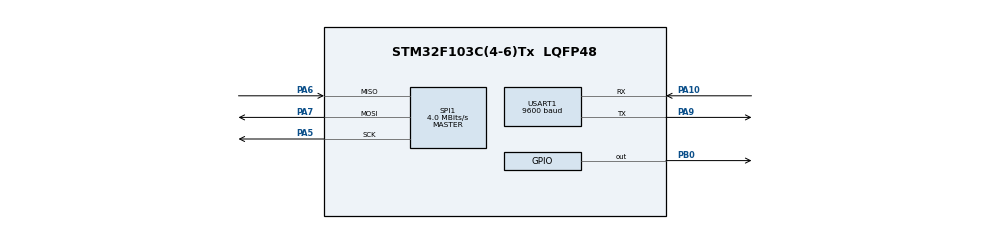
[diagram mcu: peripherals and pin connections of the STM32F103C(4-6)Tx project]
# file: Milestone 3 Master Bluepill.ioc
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Mcu.Family=STM32F1
Mcu.Name=STM32F103C(4-6)Tx
Mcu.Package=LQFP48
NVIC.PriorityGroup=NVIC_PRIORITYGROUP_4
PA10.Mode=Asynchronous
PA10.Signal=USART1_RX
PA5.Mode=Full_Duplex_Master
PA5.Signal=SPI1_SCK
PA6.Mode=Full_Duplex_Master
PA6.Signal=SPI1_MISO
PA7.Mode=Full_Duplex_Master
PA7.Signal=SPI1_MOSI
PA9.Mode=Asynchronous
PA9.Signal=USART1_TX
PB0.Signal=GPIO_Output
ProjectManager.HeapSize=0x200
ProjectManager.StackSize=0x400
ProjectManager.TargetToolchain=STM32CubeIDE
RCC.APB1Freq_Value=8000000
RCC.APB2Freq_Value=8000000
SPI1.CalculateBaudRate=4.0 MBits/s
SPI1.Direction=SPI_DIRECTION_2LINES
SPI1.Mode=SPI_MODE_MASTER
SPI1.VirtualType=VM_MASTER
USART1.BaudRate=9600
USART1.VirtualMode=VM_ASYNC
VP_SYS_VS_ND.Mode=No_Debug
board=custom

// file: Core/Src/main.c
/* USER CODE BEGIN Header */
/**
  ******************************************************************************
  * @file           : main.c
  * @brief          : Main program body
  ******************************************************************************
  * @attention
  *
  * Copyright (c) 2026 STMicroelectronics.
  * All rights reserved.
  *
  * This software is licensed under terms that can be found in the LICENSE file
  * in the root directory of this software component.
  * If no LICENSE file comes with this software, it is provided AS-IS.
  *
  ******************************************************************************
  */
/* USER CODE END Header */
#include "main.h"
#include "string.h"
#include <stdio.h>
#include <stdlib.h>

SPI_HandleTypeDef hspi1;

UART_HandleTypeDef huart1;

void SystemClock_Config(void);
static void MX_GPIO_Init(void);
static void MX_SPI1_Init(void);
static void MX_USART1_UART_Init(void);

/* USER CODE BEGIN 0 */

#pragma pack(push, 1)
struct motor_data {
    uint8_t voltage_x10; // 1 byte
    uint16_t speed;      // 2 bytes
};                       // total = 3 bytes = 24 bits
#pragma pack(pop)

/* USER CODE END 0 */
void UART_ReadLine(UART_HandleTypeDef *huart, char *buf, uint16_t max_len)
{
    uint16_t idx = 0;
    uint8_t ch = 0;

    while (idx < max_len - 1)
    {
        // Receive 1 byte (blocking)
        if (HAL_UART_Receive(huart, &ch, 1, HAL_MAX_DELAY) == HAL_OK)
        {
            // Echo character back to the terminal so the user sees what they type
            HAL_UART_Transmit(huart, &ch, 1, 10);

            // Handle newline or carriage return
            if (ch == '\r' || ch == '\n')
            {
                if (idx > 0) break; // Avoid empty inputs if terminal sends \r\n together
                continue;
            }
            // Handle backspace
            else if (ch == '\b' || ch == 127)
            {
                if (idx > 0)
                {
                    idx--;
                    // Erase character on terminal screen
                    char bs_seq[] = " \b";
                    HAL_UART_Transmit(huart, (uint8_t *)bs_seq, 2, 10);
                }
            }
            else
            {
                buf[idx++] = (char)ch;
            }
        }
    }
    buf[idx] = '\0'; // Null-terminate string

    // Print newline on terminal
    char newline[] = "\r\n";
    HAL_UART_Transmit(huart, (uint8_t *)newline, 2, 10);
}

int main(void)
{

  /* MCU Configuration--------------------------------------------------------*/

  /* Reset of all peripherals, Initializes the Flash interface and the Systick. */
  HAL_Init();

  /* Configure the system clock */
  SystemClock_Config();

  /* Initialize all configured peripherals */
  MX_GPIO_Init();
  MX_SPI1_Init();
  MX_USART1_UART_Init();
  /* USER CODE BEGIN 2 */
  struct motor_data rx_data;

  uint16_t case_id = 0x1001;

  const char first_msg[] = "Please enter case id: 0x";
  char send_msg_buffer[50];
  char receive_msg_buffer[32];
  /* USER CODE END 2 */

  /* Infinite loop */
  /* USER CODE BEGIN WHILE */
  while (1)
    {
	  HAL_UART_Transmit(&huart1, (uint8_t*)first_msg, strlen(first_msg), 100);

	  UART_ReadLine(&huart1, receive_msg_buffer, sizeof(receive_msg_buffer));

	  // Convert ASCII hex string to uint16_t
	  case_id = (uint16_t) strtol(receive_msg_buffer, NULL, 16);

      HAL_GPIO_WritePin(GPIOB, GPIO_PIN_0, GPIO_PIN_RESET);
      HAL_SPI_Transmit(&hspi1, (uint8_t *)&case_id, sizeof(case_id), 100);
      HAL_SPI_Receive(&hspi1, (uint8_t *)&rx_data, sizeof(rx_data), 100);
      HAL_GPIO_WritePin(GPIOB, GPIO_PIN_0, GPIO_PIN_SET);

      //PRINT DATA
      snprintf(send_msg_buffer, sizeof(send_msg_buffer),
                   "Voltage: %d.%d V | Speed: %u RPM\r\n",
                   rx_data.voltage_x10 / 10, rx_data.voltage_x10 % 10, rx_data.speed);

      HAL_UART_Transmit(&huart1, (uint8_t*)send_msg_buffer, strlen(send_msg_buffer), 100);

      HAL_Delay(500);
    }
  /* USER CODE END 3 */
}

void SystemClock_Config(void)
{
  RCC_OscInitTypeDef RCC_OscInitStruct = {0};
  RCC_ClkInitTypeDef RCC_ClkInitStruct = {0};

  /** Initializes the RCC Oscillators according to the specified parameters
  * in the RCC_OscInitTypeDef structure.
  */
  RCC_OscInitStruct.OscillatorType = RCC_OSCILLATORTYPE_HSI;
  RCC_OscInitStruct.HSIState = RCC_HSI_ON;
  RCC_OscInitStruct.HSICalibrationValue = RCC_HSICALIBRATION_DEFAULT;
  RCC_OscInitStruct.PLL.PLLState = RCC_PLL_NONE;
  if (HAL_RCC_OscConfig(&RCC_OscInitStruct) != HAL_OK)
  {
    Error_Handler();
  }

  /** Initializes the CPU, AHB and APB buses clocks
  */
  RCC_ClkInitStruct.ClockType = RCC_CLOCKTYPE_HCLK|RCC_CLOCKTYPE_SYSCLK
                              |RCC_CLOCKTYPE_PCLK1|RCC_CLOCKTYPE_PCLK2;
  RCC_ClkInitStruct.SYSCLKSource = RCC_SYSCLKSOURCE_HSI;
  RCC_ClkInitStruct.AHBCLKDivider = RCC_SYSCLK_DIV1;
  RCC_ClkInitStruct.APB1CLKDivider = RCC_HCLK_DIV1;
  RCC_ClkInitStruct.APB2CLKDivider = RCC_HCLK_DIV1;

  if (HAL_RCC_ClockConfig(&RCC_ClkInitStruct, FLASH_LATENCY_0) != HAL_OK)
  {
    Error_Handler();
  }
}

static void MX_SPI1_Init(void)
{

  /* SPI1 parameter configuration*/
  hspi1.Instance = SPI1;
  hspi1.Init.Mode = SPI_MODE_MASTER;
  hspi1.Init.Direction = SPI_DIRECTION_2LINES;
  hspi1.Init.DataSize = SPI_DATASIZE_8BIT;
  hspi1.Init.CLKPolarity = SPI_POLARITY_LOW;
  hspi1.Init.CLKPhase = SPI_PHASE_1EDGE;
  hspi1.Init.NSS = SPI_NSS_SOFT;
  hspi1.Init.BaudRatePrescaler = SPI_BAUDRATEPRESCALER_256;
  hspi1.Init.FirstBit = SPI_FIRSTBIT_MSB;
  hspi1.Init.TIMode = SPI_TIMODE_DISABLE;
  hspi1.Init.CRCCalculation = SPI_CRCCALCULATION_DISABLE;
  hspi1.Init.CRCPolynomial = 10;
  if (HAL_SPI_Init(&hspi1) != HAL_OK)
  {
    Error_Handler();
  }

}

static void MX_USART1_UART_Init(void)
{

  huart1.Instance = USART1;
  huart1.Init.BaudRate = 9600;
  huart1.Init.WordLength = UART_WORDLENGTH_8B;
  huart1.Init.StopBits = UART_STOPBITS_1;
  huart1.Init.Parity = UART_PARITY_NONE;
  huart1.Init.Mode = UART_MODE_TX_RX;
  huart1.Init.HwFlowCtl = UART_HWCONTROL_NONE;
  huart1.Init.OverSampling = UART_OVERSAMPLING_16;
  if (HAL_UART_Init(&huart1) != HAL_OK)
  {
    Error_Handler();
  }

}

static void MX_GPIO_Init(void)
{
  GPIO_InitTypeDef GPIO_InitStruct = {0};

  /* GPIO Ports Clock Enable */
  __HAL_RCC_GPIOA_CLK_ENABLE();
  __HAL_RCC_GPIOB_CLK_ENABLE();

  /*Configure GPIO pin Output Level */
  HAL_GPIO_WritePin(GPIOB, GPIO_PIN_0, GPIO_PIN_SET);

  /*Configure GPIO pin : PB0 */
  GPIO_InitStruct.Pin = GPIO_PIN_0;
  GPIO_InitStruct.Mode = GPIO_MODE_OUTPUT_PP;
  GPIO_InitStruct.Pull = GPIO_NOPULL;
  GPIO_InitStruct.Speed = GPIO_SPEED_FREQ_LOW;
  HAL_GPIO_Init(GPIOB, &GPIO_InitStruct);

}

void Error_Handler(void)
{
  __disable_irq();
  while (1)
  {
  }
}
